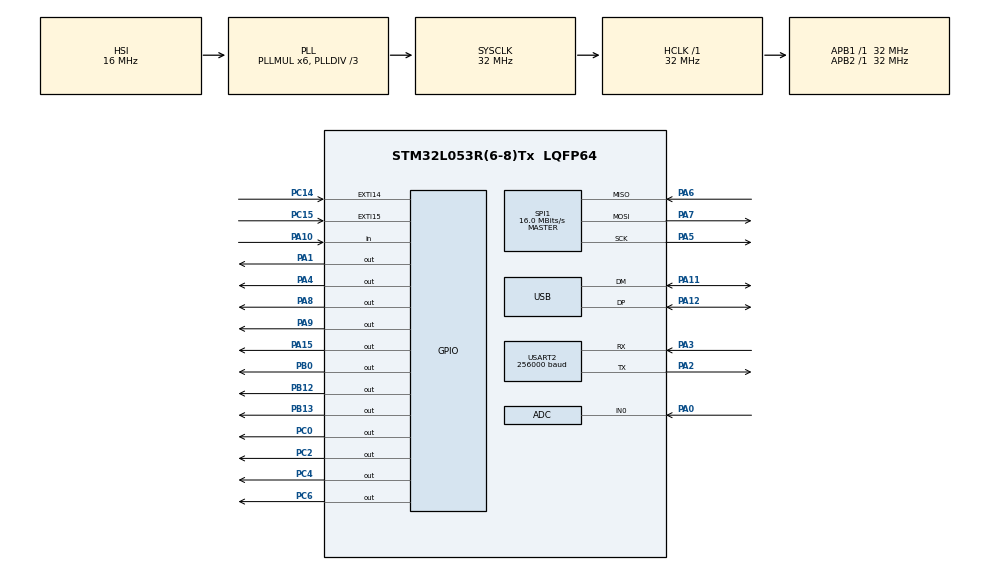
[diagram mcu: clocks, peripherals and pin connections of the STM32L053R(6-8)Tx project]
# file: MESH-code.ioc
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ADC.OversamplingMode=DISABLE
ADC.SamplingTime=ADC_SAMPLETIME_19CYCLES_5
Mcu.Family=STM32L0
Mcu.Name=STM32L053R(6-8)Tx
Mcu.Package=LQFP64
NVIC.EXTI4_15_IRQn=true\:3\:0\:true\:false\:true\:true\:true\:true
NVIC.USB_IRQn=true\:0\:0\:false\:false\:true\:false\:true\:true
PA0.Mode=IN0
PA0.Signal=ADC_IN0
PA1.Signal=GPIO_Output
PA10.Signal=GPIO_Input
PA11.Mode=Device
PA11.Signal=USB_DM
PA12.Mode=Device
PA12.Signal=USB_DP
PA13.Mode=Serial_Wire
PA13.Signal=SYS_SWDIO
PA14.Mode=Serial_Wire
PA14.Signal=SYS_SWCLK
PA15.Signal=GPIO_Output
PA2.Mode=Asynchronous
PA2.Signal=USART2_TX
PA3.Mode=Asynchronous
PA3.Signal=USART2_RX
PA4.Signal=GPIO_Output
PA5.Mode=Full_Duplex_Master
PA5.Signal=SPI1_SCK
PA6.Mode=Full_Duplex_Master
PA6.Signal=SPI1_MISO
PA7.Mode=Full_Duplex_Master
PA7.Signal=SPI1_MOSI
PA8.Signal=GPIO_Output
PA9.Signal=GPIO_Output
PB0.Signal=GPIO_Output
PB1.Signal=ADC_IN9
PB12.Signal=GPIO_Output
PB13.Signal=GPIO_Output
PC0.Signal=GPIO_Output
PC14-OSC32_IN.Signal=GPXTI14
PC15-OSC32_OUT.GPIO_ModeDefaultEXTI=GPIO_MODE_IT_FALLING
PC15-OSC32_OUT.Signal=GPXTI15
PC2.Signal=GPIO_Output
PC4.Signal=GPIO_Output
PC6.Signal=GPIO_Output
ProjectManager.HeapSize=0x200
ProjectManager.StackSize=0x400
ProjectManager.TargetToolchain=CMake
RCC.AHBFreq_Value=32000000
RCC.APB1Freq_Value=32000000
RCC.APB1TimFreq_Value=32000000
RCC.APB2Freq_Value=32000000
RCC.APB2TimFreq_Value=32000000
RCC.HCLKFreq_Value=32000000
RCC.HSE_VALUE=8000000
RCC.HSI16_VALUE=16000000
RCC.HSI48MClockSelection=RCC_USBCLKSOURCE_HSI48
RCC.HSI48_VALUE=48000000
RCC.HSI_VALUE=16000000
RCC.LSE_VALUE=32768
RCC.MSI_VALUE=2097000
RCC.PLLDIV=RCC_PLLDIV_3
RCC.PLLMUL=RCC_PLLMUL_6
RCC.SYSCLKFreq_VALUE=32000000
RCC.SYSCLKSource=RCC_SYSCLKSOURCE_PLLCLK
RCC.VCOOutputFreq_Value=96000000
SPI1.BaudRatePrescaler=SPI_BAUDRATEPRESCALER_2
SPI1.CalculateBaudRate=16.0 MBits/s
SPI1.Direction=SPI_DIRECTION_2LINES
SPI1.Mode=SPI_MODE_MASTER
SPI1.VirtualType=VM_MASTER
TIM6.Prescaler=32
USART2.BaudRate=256000
USART2.VirtualMode-Asynchronous=VM_ASYNC
USB_DEVICE.APP_RX_DATA_SIZE=64
USB_DEVICE.APP_TX_DATA_SIZE=64
USB_DEVICE.CLASS_NAME_FS=CDC
USB_DEVICE.USBD_MAX_STR_DESC_SIZ=64
USB_DEVICE.VirtualMode=Cdc
USB_DEVICE.VirtualModeFS=Cdc_FS
VP_CRC_VS_CRC.Mode=CRC_Activate
VP_RNG_VS_RNG.Mode=RNG_Activate
VP_TIM6_VS_ClockSourceINT.Mode=Enable_Timer
VP_USB_DEVICE_VS_USB_DEVICE_CDC_FS.Mode=CDC_FS
board=custom

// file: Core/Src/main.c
/* USER CODE BEGIN Header */
/**
  ******************************************************************************
  * @file           : main.c
  * @brief          : Main program body
  ******************************************************************************
  * @attention
  *
  * Copyright (c) 2025 STMicroelectronics.
  * All rights reserved.
  *
  * This software is licensed under terms that can be found in the LICENSE file
  * in the root directory of this software component.
  * If no LICENSE file comes with this software, it is provided AS-IS.
  *
  ******************************************************************************
  */
/* USER CODE END Header */
#include "main.h"
#include "usb_device.h"

/* USER CODE BEGIN Includes */
#include "appMain.h"
#include "usbd_cdc_if.h"
#include <stdio.h>
/* USER CODE END Includes */

ADC_HandleTypeDef hadc;

CRC_HandleTypeDef hcrc;

RNG_HandleTypeDef hrng;

SPI_HandleTypeDef hspi1;

TIM_HandleTypeDef htim6;

UART_HandleTypeDef huart2;

void SystemClock_Config(void);
static void MX_GPIO_Init(void);
static void MX_SPI1_Init(void);
static void MX_USART2_UART_Init(void);
static void MX_TIM6_Init(void);
static void MX_CRC_Init(void);
static void MX_RNG_Init(void);
static void MX_ADC_Init(void);

int main(void)
{

  /* MCU Configuration--------------------------------------------------------*/

  /* Reset of all peripherals, Initializes the Flash interface and the Systick. */
  HAL_Init();

  /* Configure the system clock */
  SystemClock_Config();

  /* Initialize all configured peripherals */
  MX_GPIO_Init();
  MX_SPI1_Init();
  MX_USART2_UART_Init();
  MX_USB_DEVICE_Init();
  MX_TIM6_Init();
  MX_CRC_Init();
  MX_RNG_Init();
  MX_ADC_Init();
  /* USER CODE BEGIN 2 */
    appMain(&hadc, &hspi1, 0, &htim6, &huart2,&hcrc,&hrng);
  /* USER CODE END 2 */

  /* Infinite loop */
    while (1) {

    }
}

void SystemClock_Config(void)
{
  RCC_OscInitTypeDef RCC_OscInitStruct = {0};
  RCC_ClkInitTypeDef RCC_ClkInitStruct = {0};
  RCC_PeriphCLKInitTypeDef PeriphClkInit = {0};

  /** Configure the main internal regulator output voltage
  */
  __HAL_PWR_VOLTAGESCALING_CONFIG(PWR_REGULATOR_VOLTAGE_SCALE1);

  /** Initializes the RCC Oscillators according to the specified parameters
  * in the RCC_OscInitTypeDef structure.
  */
  RCC_OscInitStruct.OscillatorType = RCC_OSCILLATORTYPE_HSI|RCC_OSCILLATORTYPE_HSI48;
  RCC_OscInitStruct.HSIState = RCC_HSI_ON;
  RCC_OscInitStruct.HSICalibrationValue = RCC_HSICALIBRATION_DEFAULT;
  RCC_OscInitStruct.HSI48State = RCC_HSI48_ON;
  RCC_OscInitStruct.PLL.PLLState = RCC_PLL_ON;
  RCC_OscInitStruct.PLL.PLLSource = RCC_PLLSOURCE_HSI;
  RCC_OscInitStruct.PLL.PLLMUL = RCC_PLLMUL_6;
  RCC_OscInitStruct.PLL.PLLDIV = RCC_PLLDIV_3;
  if (HAL_RCC_OscConfig(&RCC_OscInitStruct) != HAL_OK)
  {
    Error_Handler();
  }

  /** Initializes the CPU, AHB and APB buses clocks
  */
  RCC_ClkInitStruct.ClockType = RCC_CLOCKTYPE_HCLK|RCC_CLOCKTYPE_SYSCLK
                              |RCC_CLOCKTYPE_PCLK1|RCC_CLOCKTYPE_PCLK2;
  RCC_ClkInitStruct.SYSCLKSource = RCC_SYSCLKSOURCE_PLLCLK;
  RCC_ClkInitStruct.AHBCLKDivider = RCC_SYSCLK_DIV1;
  RCC_ClkInitStruct.APB1CLKDivider = RCC_HCLK_DIV1;
  RCC_ClkInitStruct.APB2CLKDivider = RCC_HCLK_DIV1;

  if (HAL_RCC_ClockConfig(&RCC_ClkInitStruct, FLASH_LATENCY_1) != HAL_OK)
  {
    Error_Handler();
  }
  PeriphClkInit.PeriphClockSelection = RCC_PERIPHCLK_USART2|RCC_PERIPHCLK_USB;
  PeriphClkInit.Usart2ClockSelection = RCC_USART2CLKSOURCE_PCLK1;
  PeriphClkInit.UsbClockSelection = RCC_USBCLKSOURCE_HSI48;
  if (HAL_RCCEx_PeriphCLKConfig(&PeriphClkInit) != HAL_OK)
  {
    Error_Handler();
  }
}

static void MX_ADC_Init(void)
{

  ADC_ChannelConfTypeDef sConfig = {0};

  /** Configure the global features of the ADC (Clock, Resolution, Data Alignment and number of conversion)
  */
  hadc.Instance = ADC1;
  hadc.Init.OversamplingMode = DISABLE;
  hadc.Init.ClockPrescaler = ADC_CLOCK_SYNC_PCLK_DIV2;
  hadc.Init.Resolution = ADC_RESOLUTION_12B;
  hadc.Init.SamplingTime = ADC_SAMPLETIME_19CYCLES_5;
  hadc.Init.ScanConvMode = ADC_SCAN_DIRECTION_FORWARD;
  hadc.Init.DataAlign = ADC_DATAALIGN_RIGHT;
  hadc.Init.ContinuousConvMode = DISABLE;
  hadc.Init.DiscontinuousConvMode = DISABLE;
  hadc.Init.ExternalTrigConvEdge = ADC_EXTERNALTRIGCONVEDGE_NONE;
  hadc.Init.ExternalTrigConv = ADC_SOFTWARE_START;
  hadc.Init.DMAContinuousRequests = DISABLE;
  hadc.Init.EOCSelection = ADC_EOC_SINGLE_CONV;
  hadc.Init.Overrun = ADC_OVR_DATA_PRESERVED;
  hadc.Init.LowPowerAutoWait = DISABLE;
  hadc.Init.LowPowerFrequencyMode = DISABLE;
  hadc.Init.LowPowerAutoPowerOff = DISABLE;
  if (HAL_ADC_Init(&hadc) != HAL_OK)
  {
    Error_Handler();
  }

  /** Configure for the selected ADC regular channel to be converted.
  */
  sConfig.Channel = ADC_CHANNEL_0;
  sConfig.Rank = ADC_RANK_CHANNEL_NUMBER;
  if (HAL_ADC_ConfigChannel(&hadc, &sConfig) != HAL_OK)
  {
    Error_Handler();
  }

}

static void MX_CRC_Init(void)
{

  hcrc.Instance = CRC;
  hcrc.Init.DefaultPolynomialUse = DEFAULT_POLYNOMIAL_ENABLE;
  hcrc.Init.DefaultInitValueUse = DEFAULT_INIT_VALUE_ENABLE;
  hcrc.Init.InputDataInversionMode = CRC_INPUTDATA_INVERSION_NONE;
  hcrc.Init.OutputDataInversionMode = CRC_OUTPUTDATA_INVERSION_DISABLE;
  hcrc.InputDataFormat = CRC_INPUTDATA_FORMAT_BYTES;
  if (HAL_CRC_Init(&hcrc) != HAL_OK)
  {
    Error_Handler();
  }

}

static void MX_RNG_Init(void)
{

  hrng.Instance = RNG;
  if (HAL_RNG_Init(&hrng) != HAL_OK)
  {
    Error_Handler();
  }

}

static void MX_SPI1_Init(void)
{

  /* SPI1 parameter configuration*/
  hspi1.Instance = SPI1;
  hspi1.Init.Mode = SPI_MODE_MASTER;
  hspi1.Init.Direction = SPI_DIRECTION_2LINES;
  hspi1.Init.DataSize = SPI_DATASIZE_8BIT;
  hspi1.Init.CLKPolarity = SPI_POLARITY_LOW;
  hspi1.Init.CLKPhase = SPI_PHASE_1EDGE;
  hspi1.Init.NSS = SPI_NSS_SOFT;
  hspi1.Init.BaudRatePrescaler = SPI_BAUDRATEPRESCALER_2;
  hspi1.Init.FirstBit = SPI_FIRSTBIT_MSB;
  hspi1.Init.TIMode = SPI_TIMODE_DISABLE;
  hspi1.Init.CRCCalculation = SPI_CRCCALCULATION_DISABLE;
  hspi1.Init.CRCPolynomial = 7;
  if (HAL_SPI_Init(&hspi1) != HAL_OK)
  {
    Error_Handler();
  }

}

static void MX_TIM6_Init(void)
{

  TIM_MasterConfigTypeDef sMasterConfig = {0};

  htim6.Instance = TIM6;
  htim6.Init.Prescaler = 32;
  htim6.Init.CounterMode = TIM_COUNTERMODE_UP;
  htim6.Init.Period = 65535;
  htim6.Init.AutoReloadPreload = TIM_AUTORELOAD_PRELOAD_DISABLE;
  if (HAL_TIM_Base_Init(&htim6) != HAL_OK)
  {
    Error_Handler();
  }
  sMasterConfig.MasterOutputTrigger = TIM_TRGO_RESET;
  sMasterConfig.MasterSlaveMode = TIM_MASTERSLAVEMODE_DISABLE;
  if (HAL_TIMEx_MasterConfigSynchronization(&htim6, &sMasterConfig) != HAL_OK)
  {
    Error_Handler();
  }

}

static void MX_USART2_UART_Init(void)
{

  huart2.Instance = USART2;
  huart2.Init.BaudRate = 256000;
  huart2.Init.WordLength = UART_WORDLENGTH_8B;
  huart2.Init.StopBits = UART_STOPBITS_1;
  huart2.Init.Parity = UART_PARITY_NONE;
  huart2.Init.Mode = UART_MODE_TX_RX;
  huart2.Init.HwFlowCtl = UART_HWCONTROL_NONE;
  huart2.Init.OverSampling = UART_OVERSAMPLING_16;
  huart2.Init.OneBitSampling = UART_ONE_BIT_SAMPLE_DISABLE;
  huart2.AdvancedInit.AdvFeatureInit = UART_ADVFEATURE_NO_INIT;
  if (HAL_UART_Init(&huart2) != HAL_OK)
  {
    Error_Handler();
  }

}

static void MX_GPIO_Init(void)
{
  GPIO_InitTypeDef GPIO_InitStruct = {0};

  /* GPIO Ports Clock Enable */
  __HAL_RCC_GPIOC_CLK_ENABLE();
  __HAL_RCC_GPIOH_CLK_ENABLE();
  __HAL_RCC_GPIOA_CLK_ENABLE();
  __HAL_RCC_GPIOB_CLK_ENABLE();
  __HAL_RCC_GPIOD_CLK_ENABLE();

  /*Configure GPIO pin Output Level */
  HAL_GPIO_WritePin(GPIOC, GPIO_PIN_0|GPIO_PIN_2|GPIO_PIN_4|GPIO_PIN_6, GPIO_PIN_RESET);

  /*Configure GPIO pin Output Level */
  HAL_GPIO_WritePin(GPIOA, GPIO_PIN_1|GPIO_PIN_4|GPIO_PIN_8|GPIO_PIN_9
                          |GPIO_PIN_15, GPIO_PIN_RESET);

  /*Configure GPIO pin Output Level */
  HAL_GPIO_WritePin(GPIOB, GPIO_PIN_0|GPIO_PIN_12|GPIO_PIN_13, GPIO_PIN_RESET);

  /*Configure GPIO pins : PC13 PC1 PC3 PC5
                           PC7 PC8 PC9 PC10
                           PC11 PC12 */
  GPIO_InitStruct.Pin = GPIO_PIN_13|GPIO_PIN_1|GPIO_PIN_3|GPIO_PIN_5
                          |GPIO_PIN_7|GPIO_PIN_8|GPIO_PIN_9|GPIO_PIN_10
                          |GPIO_PIN_11|GPIO_PIN_12;
  GPIO_InitStruct.Mode = GPIO_MODE_ANALOG;
  GPIO_InitStruct.Pull = GPIO_NOPULL;
  HAL_GPIO_Init(GPIOC, &GPIO_InitStruct);

  /*Configure GPIO pin : PC14 */
  GPIO_InitStruct.Pin = GPIO_PIN_14;
  GPIO_InitStruct.Mode = GPIO_MODE_IT_RISING;
  GPIO_InitStruct.Pull = GPIO_NOPULL;
  HAL_GPIO_Init(GPIOC, &GPIO_InitStruct);

  /*Configure GPIO pin : PC15 */
  GPIO_InitStruct.Pin = GPIO_PIN_15;
  GPIO_InitStruct.Mode = GPIO_MODE_IT_FALLING;
  GPIO_InitStruct.Pull = GPIO_NOPULL;
  HAL_GPIO_Init(GPIOC, &GPIO_InitStruct);

  /*Configure GPIO pins : PH0 PH1 */
  GPIO_InitStruct.Pin = GPIO_PIN_0|GPIO_PIN_1;
  GPIO_InitStruct.Mode = GPIO_MODE_ANALOG;
  GPIO_InitStruct.Pull = GPIO_NOPULL;
  HAL_GPIO_Init(GPIOH, &GPIO_InitStruct);

  /*Configure GPIO pins : PC0 PC2 PC4 PC6 */
  GPIO_InitStruct.Pin = GPIO_PIN_0|GPIO_PIN_2|GPIO_PIN_4|GPIO_PIN_6;
  GPIO_InitStruct.Mode = GPIO_MODE_OUTPUT_PP;
  GPIO_InitStruct.Pull = GPIO_NOPULL;
  GPIO_InitStruct.Speed = GPIO_SPEED_FREQ_LOW;
  HAL_GPIO_Init(GPIOC, &GPIO_InitStruct);

  /*Configure GPIO pins : PA1 PA4 PA8 PA9
                           PA15 */
  GPIO_InitStruct.Pin = GPIO_PIN_1|GPIO_PIN_4|GPIO_PIN_8|GPIO_PIN_9
                          |GPIO_PIN_15;
  GPIO_InitStruct.Mode = GPIO_MODE_OUTPUT_PP;
  GPIO_InitStruct.Pull = GPIO_NOPULL;
  GPIO_InitStruct.Speed = GPIO_SPEED_FREQ_LOW;
  HAL_GPIO_Init(GPIOA, &GPIO_InitStruct);

  /*Configure GPIO pins : PB0 PB12 PB13 */
  GPIO_InitStruct.Pin = GPIO_PIN_0|GPIO_PIN_12|GPIO_PIN_13;
  GPIO_InitStruct.Mode = GPIO_MODE_OUTPUT_PP;
  GPIO_InitStruct.Pull = GPIO_NOPULL;
  GPIO_InitStruct.Speed = GPIO_SPEED_FREQ_LOW;
  HAL_GPIO_Init(GPIOB, &GPIO_InitStruct);

  /*Configure GPIO pins : PB2 PB10 PB11 PB14
                           PB15 PB3 PB4 PB5
                           PB6 PB7 PB8 PB9 */
  GPIO_InitStruct.Pin = GPIO_PIN_2|GPIO_PIN_10|GPIO_PIN_11|GPIO_PIN_14
                          |GPIO_PIN_15|GPIO_PIN_3|GPIO_PIN_4|GPIO_PIN_5
                          |GPIO_PIN_6|GPIO_PIN_7|GPIO_PIN_8|GPIO_PIN_9;
  GPIO_InitStruct.Mode = GPIO_MODE_ANALOG;
  GPIO_InitStruct.Pull = GPIO_NOPULL;
  HAL_GPIO_Init(GPIOB, &GPIO_InitStruct);

  /*Configure GPIO pin : PA10 */
  GPIO_InitStruct.Pin = GPIO_PIN_10;
  GPIO_InitStruct.Mode = GPIO_MODE_INPUT;
  GPIO_InitStruct.Pull = GPIO_NOPULL;
  HAL_GPIO_Init(GPIOA, &GPIO_InitStruct);

  /*Configure GPIO pin : PD2 */
  GPIO_InitStruct.Pin = GPIO_PIN_2;
  GPIO_InitStruct.Mode = GPIO_MODE_ANALOG;
  GPIO_InitStruct.Pull = GPIO_NOPULL;
  HAL_GPIO_Init(GPIOD, &GPIO_InitStruct);

  /* EXTI interrupt init*/
  HAL_NVIC_SetPriority(EXTI4_15_IRQn, 3, 0);
  HAL_NVIC_EnableIRQ(EXTI4_15_IRQn);

}

/* USER CODE BEGIN 4 */
int _write(int file, char *ptr, int len) {
    static uint8_t rc = USBD_OK;
    rc = CDC_Transmit_FS(ptr, len);
    HAL_Delay(1);
    if (USBD_FAIL == rc) {
        /// NOTE: Should never reach here.
        /// TODO: Handle this error.
        return 0;
    }
    return len;
}

/* USER CODE END 4 */

void Error_Handler(void)
{
    __disable_irq();
    while (1) {
    }
}
